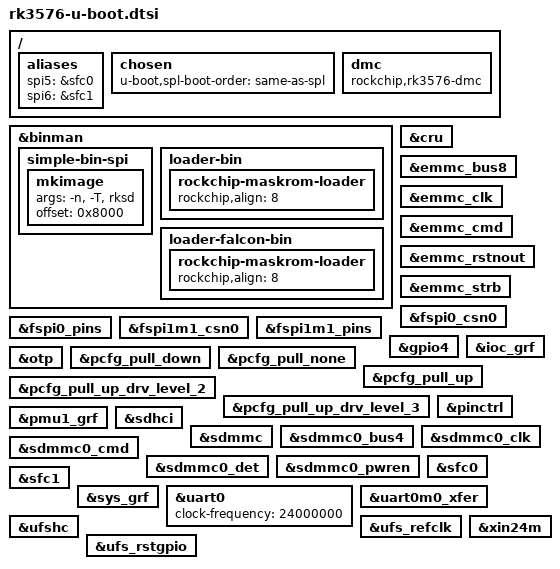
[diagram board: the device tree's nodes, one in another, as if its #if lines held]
// SPDX-License-Identifier: (GPL-2.0+ OR MIT)
/*
 * (C) Copyright 2025 Rockchip Electronics Co., Ltd
 */

#include "rockchip-u-boot.dtsi"

/ {
	aliases {
		spi5 = &sfc0;
		spi6 = &sfc1;
	};

	chosen {
		u-boot,spl-boot-order = "same-as-spl", &sdmmc, &sdhci, &ufshc;
	};

	dmc {
		compatible = "rockchip,rk3576-dmc";
		bootph-all;
	};
};

#ifdef CONFIG_ROCKCHIP_SPI_IMAGE
&binman {
	simple-bin-spi {
		mkimage {
			args = "-n", CONFIG_SYS_SOC, "-T", "rksd";
			offset = <0x8000>;
		};
	};
};
#endif

#ifdef CONFIG_ROCKCHIP_MASKROM_IMAGE
/* boot_merger uses [SYSTEM] ALIGN=8 for this SoC, unlike the usual 4 */
&binman {
	loader-bin {
		rockchip-maskrom-loader {
			rockchip,align = <8>;
		};
	};

#ifdef CONFIG_ROCKCHIP_FALCON_IMAGE
	loader-falcon-bin {
		rockchip-maskrom-loader {
			rockchip,align = <8>;
		};
	};
#endif
};
#endif

&cru {
	bootph-all;
};

&emmc_bus8 {
	bootph-pre-ram;
	bootph-some-ram;
};

&emmc_clk {
	bootph-pre-ram;
	bootph-some-ram;
};

&emmc_cmd {
	bootph-pre-ram;
	bootph-some-ram;
};

&emmc_rstnout {
	bootph-pre-ram;
	bootph-some-ram;
};

&emmc_strb {
	bootph-pre-ram;
	bootph-some-ram;
};

&fspi0_csn0 {
	bootph-pre-ram;
	bootph-some-ram;
};

&fspi0_pins {
	bootph-pre-ram;
	bootph-some-ram;
};

&fspi1m1_csn0 {
	bootph-pre-ram;
	bootph-some-ram;
};

&fspi1m1_pins {
	bootph-pre-ram;
	bootph-some-ram;
};

#ifdef CONFIG_SPL_UFS_SUPPORT
&gpio4 {
	/* This is specifically for GPIO4_D0, which is the only 1.2V capable
	 * pin on RK3576 available for use as the UFS device reset, thus
	 * &gpio4 is required for booting from UFS on RK3576.
	 */
	bootph-pre-ram;
	bootph-some-ram;
};
#endif

&ioc_grf {
	bootph-all;
};

&otp {
	bootph-some-ram;
};

&pcfg_pull_down {
	bootph-pre-ram;
	bootph-some-ram;
};

&pcfg_pull_none {
	bootph-all;
};

&pcfg_pull_up {
	bootph-all;
};

&pcfg_pull_up_drv_level_2 {
	bootph-pre-ram;
	bootph-some-ram;
};

&pcfg_pull_up_drv_level_3 {
	bootph-pre-ram;
	bootph-some-ram;
};

&pinctrl {
	/*
	 * Keep pinctrl in SPL (bootph-pre-ram), but NOT in U-Boot proper's
	 * board_init_f: bootph-all would force a pre-relocation bind, and the
	 * driver's .bind = dm_scan_fdt_dev then walks every pin-group child
	 * against the flat DT with the D-cache off (~0.6s). With bootph-pre-ram
	 * the node binds in board_init_r instead (live tree + cache, ~13ms).
	 * Console/PMIC pins are already muxed by SPL, so pre-reloc pinctrl is
	 * not needed here.
	 */
	bootph-pre-ram;
};

&pmu1_grf {
	bootph-all;
};

&sdhci {
	bootph-pre-ram;
	bootph-some-ram;
};

&sdmmc {
	bootph-pre-ram;
	bootph-some-ram;
};

&sdmmc0_bus4 {
	bootph-pre-ram;
	bootph-some-ram;
};

&sdmmc0_clk {
	bootph-pre-ram;
	bootph-some-ram;
};

&sdmmc0_cmd {
	bootph-pre-ram;
	bootph-some-ram;
};

&sdmmc0_det {
	bootph-pre-ram;
	bootph-some-ram;
};

&sdmmc0_pwren {
	bootph-pre-ram;
	bootph-some-ram;
};

&sfc0 {
	bootph-some-ram;
};

&sfc1 {
	bootph-some-ram;
};

&sys_grf {
	bootph-all;
};

&uart0 {
	bootph-all;
	clock-frequency = <24000000>;
};

&uart0m0_xfer {
	bootph-pre-sram;
	bootph-pre-ram;
};

&ufshc {
	bootph-pre-ram;
	bootph-some-ram;
};

&ufs_refclk {
	bootph-pre-ram;
	bootph-some-ram;
};

&ufs_rstgpio {
	bootph-pre-ram;
	bootph-some-ram;
};

&xin24m {
	bootph-all;
};
